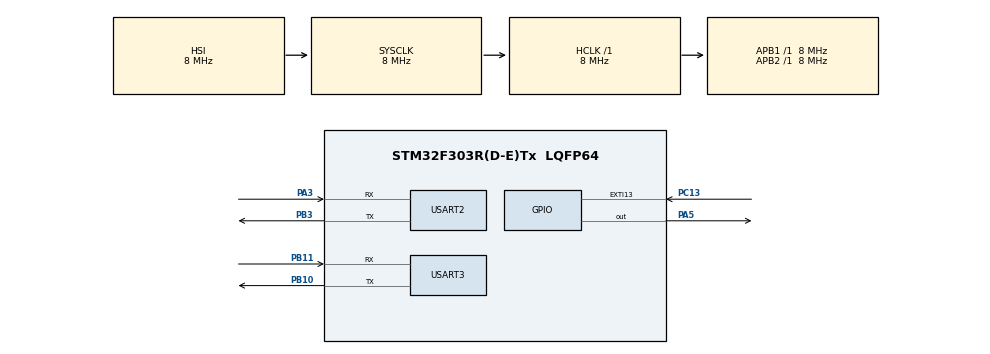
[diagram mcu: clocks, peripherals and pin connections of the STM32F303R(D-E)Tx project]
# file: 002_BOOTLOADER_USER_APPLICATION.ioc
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Mcu.Family=STM32F3
Mcu.Name=STM32F303R(D-E)Tx
Mcu.Package=LQFP64
NVIC.EXTI15_10_IRQn=true\:0\:0\:false\:false\:true\:true\:true\:true
NVIC.PriorityGroup=NVIC_PRIORITYGROUP_4
PA3.Mode=Asynchronous
PA3.Signal=USART2_RX
PA5.Signal=GPIO_Output
PB10.Mode=Asynchronous
PB10.Signal=USART3_TX
PB11.Mode=Asynchronous
PB11.Signal=USART3_RX
PB3.Mode=Asynchronous
PB3.Signal=USART2_TX
PC13.Signal=GPXTI13
ProjectManager.HeapSize=0x200
ProjectManager.StackSize=0x400
ProjectManager.TargetToolchain=STM32CubeIDE
RCC.AHBFreq_Value=8000000
RCC.APB1Freq_Value=8000000
RCC.APB2Freq_Value=8000000
RCC.CortexFreq_Value=8000000
RCC.HSE_VALUE=8000000
RCC.HSI_VALUE=8000000
RCC.LSE_VALUE=32768
RCC.SYSCLKFreq_VALUE=8000000
RCC.USBFreq_Value=16000000
USART2.VirtualMode-Asynchronous=VM_ASYNC
USART3.VirtualMode-Asynchronous=VM_ASYNC
board=custom

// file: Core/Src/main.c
/* USER CODE BEGIN Header */
/**
  ******************************************************************************
  * @file           : main.c
  * @brief          : Main program body
  ******************************************************************************
  * @attention
  *
  * Copyright (c) 2025 STMicroelectronics.
  * All rights reserved.
  *
  * This software is licensed under terms that can be found in the LICENSE file
  * in the root directory of this software component.
  * If no LICENSE file comes with this software, it is provided AS-IS.
  *
  ******************************************************************************
  */
/* USER CODE END Header */
#include "main.h"

/* USER CODE BEGIN Includes */

#include "stdarg.h"
#include "stdio.h"
#include "string.h"

/* USER CODE END Includes */

/* USER CODE BEGIN PD */

#define DEBUG_UART_PORT &huart2

/* USER CODE END PD */

UART_HandleTypeDef huart2;
UART_HandleTypeDef huart3;

void SystemClock_Config(void);
static void MX_GPIO_Init(void);
static void MX_USART2_UART_Init(void);
static void MX_USART3_UART_Init(void);

/* USER CODE BEGIN 0 */

void print_message(char* format, ...){

	char coming_message[100];

	va_list va_list;
	va_start(va_list, format);
	vsprintf(coming_message, format, va_list);
	HAL_UART_Transmit(DEBUG_UART_PORT, (uint8_t*)coming_message, strlen(coming_message), HAL_MAX_DELAY);
	va_end(va_list);
}

/* USER CODE END 0 */

int main(void)
{

  /* MCU Configuration--------------------------------------------------------*/

  /* Reset of all peripherals, Initializes the Flash interface and the Systick. */
  HAL_Init();

  /* Configure the system clock */
  SystemClock_Config();

  /* Initialize all configured peripherals */
  MX_GPIO_Init();
  MX_USART2_UART_Init();
  MX_USART3_UART_Init();

  /* Infinite loop */
  /* USER CODE BEGIN WHILE */
  while (1)
  {
	  print_message("Hello from BL user application\n");
	  HAL_GPIO_TogglePin(GPIOA, GPIO_PIN_5);
	  HAL_Delay(500);
    /* USER CODE END WHILE */

  }
}

void SystemClock_Config(void)
{
  RCC_OscInitTypeDef RCC_OscInitStruct = {0};
  RCC_ClkInitTypeDef RCC_ClkInitStruct = {0};
  RCC_PeriphCLKInitTypeDef PeriphClkInit = {0};

  /** Initializes the RCC Oscillators according to the specified parameters
  * in the RCC_OscInitTypeDef structure.
  */
  RCC_OscInitStruct.OscillatorType = RCC_OSCILLATORTYPE_HSI;
  RCC_OscInitStruct.HSIState = RCC_HSI_ON;
  RCC_OscInitStruct.HSICalibrationValue = RCC_HSICALIBRATION_DEFAULT;
  RCC_OscInitStruct.PLL.PLLState = RCC_PLL_NONE;
  if (HAL_RCC_OscConfig(&RCC_OscInitStruct) != HAL_OK)
  {
    Error_Handler();
  }

  /** Initializes the CPU, AHB and APB buses clocks
  */
  RCC_ClkInitStruct.ClockType = RCC_CLOCKTYPE_HCLK|RCC_CLOCKTYPE_SYSCLK
                              |RCC_CLOCKTYPE_PCLK1|RCC_CLOCKTYPE_PCLK2;
  RCC_ClkInitStruct.SYSCLKSource = RCC_SYSCLKSOURCE_HSI;
  RCC_ClkInitStruct.AHBCLKDivider = RCC_SYSCLK_DIV1;
  RCC_ClkInitStruct.APB1CLKDivider = RCC_HCLK_DIV1;
  RCC_ClkInitStruct.APB2CLKDivider = RCC_HCLK_DIV1;

  if (HAL_RCC_ClockConfig(&RCC_ClkInitStruct, FLASH_LATENCY_0) != HAL_OK)
  {
    Error_Handler();
  }
  PeriphClkInit.PeriphClockSelection = RCC_PERIPHCLK_USART2|RCC_PERIPHCLK_USART3;
  PeriphClkInit.Usart2ClockSelection = RCC_USART2CLKSOURCE_PCLK1;
  PeriphClkInit.Usart3ClockSelection = RCC_USART3CLKSOURCE_PCLK1;
  if (HAL_RCCEx_PeriphCLKConfig(&PeriphClkInit) != HAL_OK)
  {
    Error_Handler();
  }
}

static void MX_USART2_UART_Init(void)
{

  huart2.Instance = USART2;
  huart2.Init.BaudRate = 38400;
  huart2.Init.WordLength = UART_WORDLENGTH_8B;
  huart2.Init.StopBits = UART_STOPBITS_1;
  huart2.Init.Parity = UART_PARITY_NONE;
  huart2.Init.Mode = UART_MODE_TX_RX;
  huart2.Init.HwFlowCtl = UART_HWCONTROL_NONE;
  huart2.Init.OverSampling = UART_OVERSAMPLING_16;
  huart2.Init.OneBitSampling = UART_ONE_BIT_SAMPLE_DISABLE;
  huart2.AdvancedInit.AdvFeatureInit = UART_ADVFEATURE_NO_INIT;
  if (HAL_UART_Init(&huart2) != HAL_OK)
  {
    Error_Handler();
  }

}

static void MX_USART3_UART_Init(void)
{

  huart3.Instance = USART3;
  huart3.Init.BaudRate = 38400;
  huart3.Init.WordLength = UART_WORDLENGTH_8B;
  huart3.Init.StopBits = UART_STOPBITS_1;
  huart3.Init.Parity = UART_PARITY_NONE;
  huart3.Init.Mode = UART_MODE_TX_RX;
  huart3.Init.HwFlowCtl = UART_HWCONTROL_NONE;
  huart3.Init.OverSampling = UART_OVERSAMPLING_16;
  huart3.Init.OneBitSampling = UART_ONE_BIT_SAMPLE_DISABLE;
  huart3.AdvancedInit.AdvFeatureInit = UART_ADVFEATURE_NO_INIT;
  if (HAL_UART_Init(&huart3) != HAL_OK)
  {
    Error_Handler();
  }

}

static void MX_GPIO_Init(void)
{
  GPIO_InitTypeDef GPIO_InitStruct = {0};

  /* GPIO Ports Clock Enable */
  __HAL_RCC_GPIOC_CLK_ENABLE();
  __HAL_RCC_GPIOA_CLK_ENABLE();
  __HAL_RCC_GPIOB_CLK_ENABLE();

  /*Configure GPIO pin Output Level */
  HAL_GPIO_WritePin(GPIOA, GPIO_PIN_5, GPIO_PIN_RESET);

  /*Configure GPIO pin : PC13 */
  GPIO_InitStruct.Pin = GPIO_PIN_13;
  GPIO_InitStruct.Mode = GPIO_MODE_IT_RISING;
  GPIO_InitStruct.Pull = GPIO_NOPULL;
  HAL_GPIO_Init(GPIOC, &GPIO_InitStruct);

  /*Configure GPIO pin : PA5 */
  GPIO_InitStruct.Pin = GPIO_PIN_5;
  GPIO_InitStruct.Mode = GPIO_MODE_OUTPUT_PP;
  GPIO_InitStruct.Pull = GPIO_NOPULL;
  GPIO_InitStruct.Speed = GPIO_SPEED_FREQ_LOW;
  HAL_GPIO_Init(GPIOA, &GPIO_InitStruct);

  /* EXTI interrupt init*/
  HAL_NVIC_SetPriority(EXTI15_10_IRQn, 0, 0);
  HAL_NVIC_EnableIRQ(EXTI15_10_IRQn);

}

void Error_Handler(void)
{
  __disable_irq();
  while (1)
  {
  }
}
